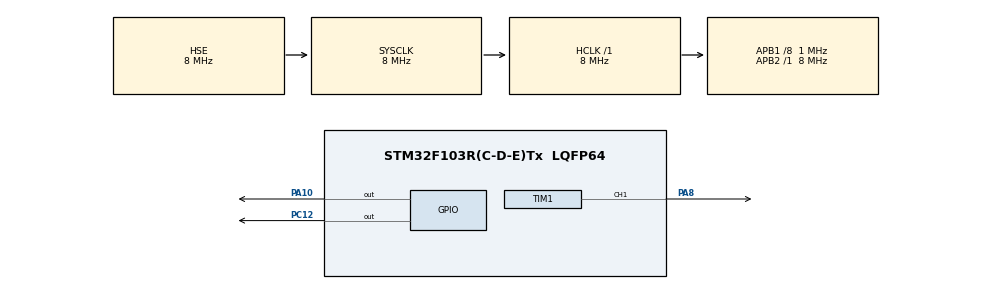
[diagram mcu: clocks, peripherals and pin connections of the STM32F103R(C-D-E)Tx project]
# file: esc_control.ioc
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Mcu.Family=STM32F1
Mcu.Name=STM32F103R(C-D-E)Tx
Mcu.Package=LQFP64
NVIC.PriorityGroup=NVIC_PRIORITYGROUP_4
PA10.Signal=GPIO_Output
PA13.Mode=Serial_Wire
PA13.Signal=SYS_JTMS-SWDIO
PA14.Mode=Serial_Wire
PA14.Signal=SYS_JTCK-SWCLK
PA8.Signal=S_TIM1_CH1
PC12.GPIO_Speed=GPIO_SPEED_FREQ_HIGH
PC12.Signal=GPIO_Output
PD0-OSC_IN.Mode=HSE-External-Oscillator
PD0-OSC_IN.Signal=RCC_OSC_IN
PD1-OSC_OUT.Mode=HSE-External-Oscillator
PD1-OSC_OUT.Signal=RCC_OSC_OUT
ProjectManager.HeapSize=0x200
ProjectManager.StackSize=0x400
ProjectManager.TargetToolchain=STM32CubeIDE
RCC.AHBFreq_Value=8000000
RCC.APB1CLKDivider=RCC_HCLK_DIV8
RCC.APB1Freq_Value=1000000
RCC.APB1TimFreq_Value=2000000
RCC.APB2Freq_Value=8000000
RCC.APB2TimFreq_Value=8000000
RCC.HCLKFreq_Value=8000000
RCC.PLLMUL=RCC_PLL_MUL9
RCC.PLLSourceVirtual=RCC_PLLSOURCE_HSE
RCC.SYSCLKFreq_VALUE=8000000
RCC.SYSCLKSource=RCC_SYSCLKSOURCE_HSE
RCC.USBFreq_Value=72000000
SH.S_TIM1_CH1.0=TIM1_CH1,PWM Generation1 CH1
TIM1.Channel-PWM\ Generation1\ CH1=TIM_CHANNEL_1
TIM1.Period=20000
board=custom

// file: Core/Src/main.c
/* USER CODE BEGIN Header */
/**
  ******************************************************************************
  * @file           : main.c
  * @brief          : Main program body
  ******************************************************************************
  * @attention
  *
  * <h2><center>&copy; Copyright (c) 2019 STMicroelectronics.
  * All rights reserved.</center></h2>
  *
  * This software component is licensed by ST under BSD 3-Clause license,
  * the "License"; You may not use this file except in compliance with the
  * License. You may obtain a copy of the License at:
  *                        opensource.org/licenses/BSD-3-Clause
  *
  ******************************************************************************
  */
/* USER CODE END Header */

#include "main.h"

TIM_HandleTypeDef htim1;

void SystemClock_Config(void);
static void MX_GPIO_Init(void);
static void MX_TIM1_Init(void);

int main(void)
{

  /* MCU Configuration--------------------------------------------------------*/

  /* Reset of all peripherals, Initializes the Flash interface and the Systick. */
  HAL_Init();

  /* Configure the system clock */
  SystemClock_Config();

  /* Initialize all configured peripherals */
  MX_GPIO_Init();
  MX_TIM1_Init();
  /* USER CODE BEGIN 2 */
	HAL_TIM_Base_Start(&htim1);
// Start PWM at Port-B pin#6
   HAL_TIM_PWM_Start(&htim1,TIM_CHANNEL_1);
  /* USER CODE END 2 */

  /* Infinite loop */
  while (1)
  {

    /* USER CODE BEGIN 3 */
	  __HAL_TIM_SET_COMPARE(&htim1, TIM_CHANNEL_1, 1500);

  }
  /* USER CODE END 3 */
}

void SystemClock_Config(void)
{
  RCC_OscInitTypeDef RCC_OscInitStruct = {0};
  RCC_ClkInitTypeDef RCC_ClkInitStruct = {0};

  /** Initializes the CPU, AHB and APB busses clocks
  */
  RCC_OscInitStruct.OscillatorType = RCC_OSCILLATORTYPE_HSE;
  RCC_OscInitStruct.HSEState = RCC_HSE_ON;
  RCC_OscInitStruct.PLL.PLLState = RCC_PLL_NONE;
  if (HAL_RCC_OscConfig(&RCC_OscInitStruct) != HAL_OK)
  {
    Error_Handler();
  }
  /** Initializes the CPU, AHB and APB busses clocks
  */
  RCC_ClkInitStruct.ClockType = RCC_CLOCKTYPE_HCLK|RCC_CLOCKTYPE_SYSCLK
                              |RCC_CLOCKTYPE_PCLK1|RCC_CLOCKTYPE_PCLK2;
  RCC_ClkInitStruct.SYSCLKSource = RCC_SYSCLKSOURCE_HSE;
  RCC_ClkInitStruct.AHBCLKDivider = RCC_SYSCLK_DIV1;
  RCC_ClkInitStruct.APB1CLKDivider = RCC_HCLK_DIV8;
  RCC_ClkInitStruct.APB2CLKDivider = RCC_HCLK_DIV1;

  if (HAL_RCC_ClockConfig(&RCC_ClkInitStruct, FLASH_LATENCY_0) != HAL_OK)
  {
    Error_Handler();
  }
}

static void MX_TIM1_Init(void)
{

  TIM_MasterConfigTypeDef sMasterConfig = {0};
  TIM_OC_InitTypeDef sConfigOC = {0};
  TIM_BreakDeadTimeConfigTypeDef sBreakDeadTimeConfig = {0};

  htim1.Instance = TIM1;
  htim1.Init.Prescaler = 0;
  htim1.Init.CounterMode = TIM_COUNTERMODE_UP;
  htim1.Init.Period = 20000;
  htim1.Init.ClockDivision = TIM_CLOCKDIVISION_DIV1;
  htim1.Init.RepetitionCounter = 0;
  htim1.Init.AutoReloadPreload = TIM_AUTORELOAD_PRELOAD_DISABLE;
  if (HAL_TIM_PWM_Init(&htim1) != HAL_OK)
  {
    Error_Handler();
  }
  sMasterConfig.MasterOutputTrigger = TIM_TRGO_RESET;
  sMasterConfig.MasterSlaveMode = TIM_MASTERSLAVEMODE_DISABLE;
  if (HAL_TIMEx_MasterConfigSynchronization(&htim1, &sMasterConfig) != HAL_OK)
  {
    Error_Handler();
  }
  sConfigOC.OCMode = TIM_OCMODE_PWM1;
  sConfigOC.Pulse = 0;
  sConfigOC.OCPolarity = TIM_OCPOLARITY_HIGH;
  sConfigOC.OCNPolarity = TIM_OCNPOLARITY_HIGH;
  sConfigOC.OCFastMode = TIM_OCFAST_DISABLE;
  sConfigOC.OCIdleState = TIM_OCIDLESTATE_RESET;
  sConfigOC.OCNIdleState = TIM_OCNIDLESTATE_RESET;
  if (HAL_TIM_PWM_ConfigChannel(&htim1, &sConfigOC, TIM_CHANNEL_1) != HAL_OK)
  {
    Error_Handler();
  }
  sBreakDeadTimeConfig.OffStateRunMode = TIM_OSSR_DISABLE;
  sBreakDeadTimeConfig.OffStateIDLEMode = TIM_OSSI_DISABLE;
  sBreakDeadTimeConfig.LockLevel = TIM_LOCKLEVEL_OFF;
  sBreakDeadTimeConfig.DeadTime = 0;
  sBreakDeadTimeConfig.BreakState = TIM_BREAK_DISABLE;
  sBreakDeadTimeConfig.BreakPolarity = TIM_BREAKPOLARITY_HIGH;
  sBreakDeadTimeConfig.AutomaticOutput = TIM_AUTOMATICOUTPUT_DISABLE;
  if (HAL_TIMEx_ConfigBreakDeadTime(&htim1, &sBreakDeadTimeConfig) != HAL_OK)
  {
    Error_Handler();
  }
  HAL_TIM_MspPostInit(&htim1);

}

static void MX_GPIO_Init(void)
{
  GPIO_InitTypeDef GPIO_InitStruct = {0};

  /* GPIO Ports Clock Enable */
  __HAL_RCC_GPIOD_CLK_ENABLE();
  __HAL_RCC_GPIOA_CLK_ENABLE();
  __HAL_RCC_GPIOC_CLK_ENABLE();

  /*Configure GPIO pin Output Level */
  HAL_GPIO_WritePin(GPIOA, GPIO_PIN_10, GPIO_PIN_RESET);

  /*Configure GPIO pin Output Level */
  HAL_GPIO_WritePin(GPIOC, GPIO_PIN_12, GPIO_PIN_RESET);

  /*Configure GPIO pin : PA10 */
  GPIO_InitStruct.Pin = GPIO_PIN_10;
  GPIO_InitStruct.Mode = GPIO_MODE_OUTPUT_PP;
  GPIO_InitStruct.Pull = GPIO_NOPULL;
  GPIO_InitStruct.Speed = GPIO_SPEED_FREQ_LOW;
  HAL_GPIO_Init(GPIOA, &GPIO_InitStruct);

  /*Configure GPIO pin : PC12 */
  GPIO_InitStruct.Pin = GPIO_PIN_12;
  GPIO_InitStruct.Mode = GPIO_MODE_OUTPUT_PP;
  GPIO_InitStruct.Pull = GPIO_NOPULL;
  GPIO_InitStruct.Speed = GPIO_SPEED_FREQ_HIGH;
  HAL_GPIO_Init(GPIOC, &GPIO_InitStruct);

}

void Error_Handler(void)
{
}

/************************ (C) COPYRIGHT STMicroelectronics *****END OF FILE****/
